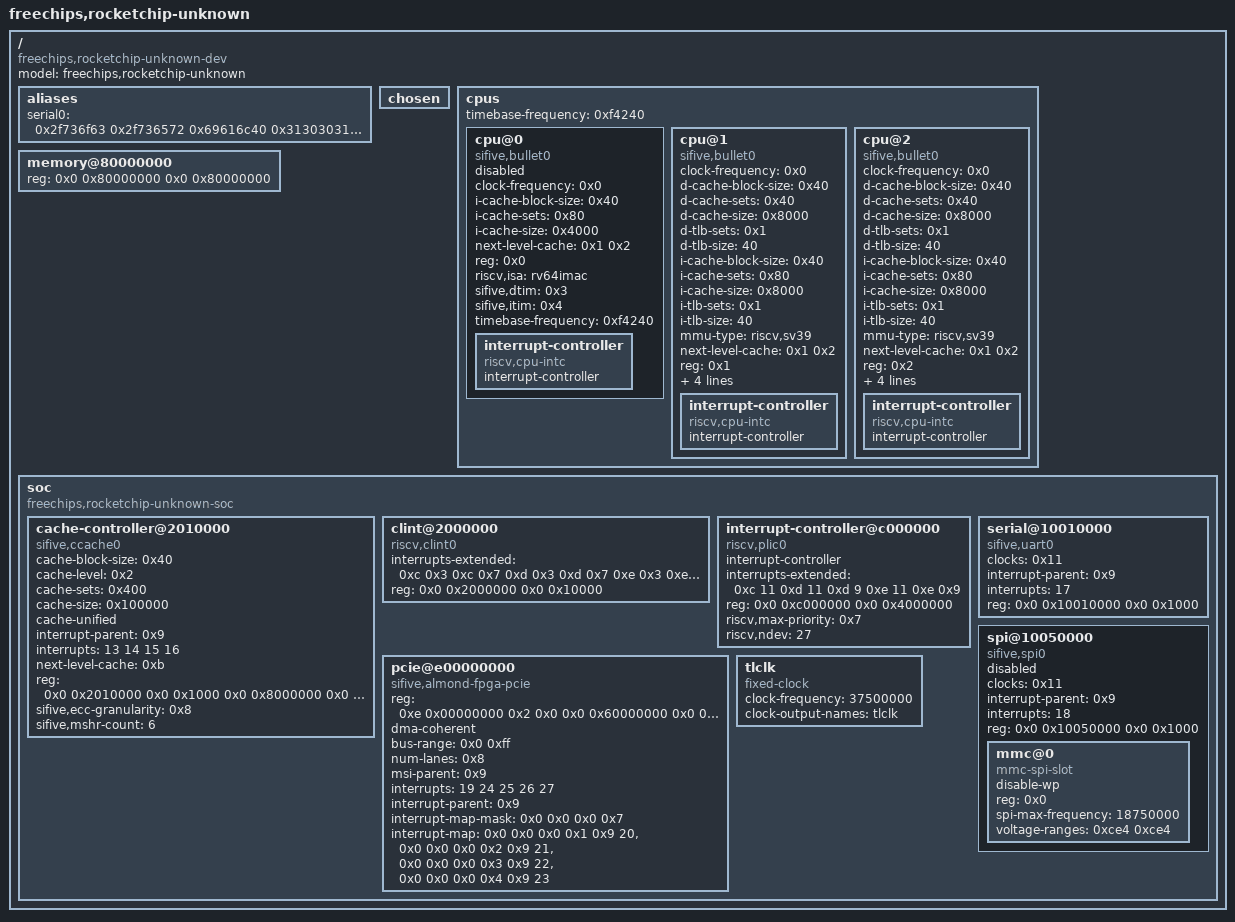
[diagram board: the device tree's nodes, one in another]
/dts-v1/;

/ {
	#address-cells = <0x2>;
	#size-cells = <0x2>;
	compatible = "freechips,rocketchip-unknown-dev";
	model = "freechips,rocketchip-unknown";

	aliases {
		serial0 = <0x2f736f63 0x2f736572 0x69616c40 0x31303031 0x30303030>;
	};

	chosen {
	};

	cpus {
		#address-cells = <0x1>;
		#size-cells = <0x0>;

                timebase-frequency = <0xf4240>;
		cpu@0 {
			clock-frequency = <0x0>;
			compatible = "sifive,bullet0", "riscv";
			device_type = "cpu";
			i-cache-block-size = <0x40>;
			i-cache-sets = <0x80>;
			i-cache-size = <0x4000>;
			next-level-cache = <0x1 0x2>;
			reg = <0x0>;
			riscv,isa = "rv64imac";
			sifive,dtim = <0x3>;
			sifive,itim = <0x4>;
			status = "masked";
			timebase-frequency = <0xf4240>;

			interrupt-controller {
				#interrupt-cells = <0x1>;
				compatible = "riscv,cpu-intc";
				interrupt-controller;
				linux,phandle = <0xc>;
				phandle = <0xc>;
			};
		};

		cpu@1 {
			clock-frequency = <0x0>;
			compatible = "sifive,bullet0", "riscv";
			d-cache-block-size = <0x40>;
			d-cache-sets = <0x40>;
			d-cache-size = <0x8000>;
			d-tlb-sets = <0x1>;
			d-tlb-size = <40>;
			device_type = "cpu";
			i-cache-block-size = <0x40>;
			i-cache-sets = <0x80>;
			i-cache-size = <0x8000>;
			i-tlb-sets = <0x1>;
			i-tlb-size = <40>;
			mmu-type = "riscv,sv39";
			next-level-cache = <0x1 0x2>;
			reg = <0x1>;
			riscv,isa = "rv64imafdc";
			sifive,itim = <0x5>;
			status = "okay";
			timebase-frequency = <0xf4240>;
			tlb-split;

			interrupt-controller {
				#interrupt-cells = <0x1>;
				compatible = "riscv,cpu-intc";
				interrupt-controller;
				linux,phandle = <0xd>;
				phandle = <0xd>;
			};
		};

		cpu@2 {
			clock-frequency = <0x0>;
			compatible = "sifive,bullet0", "riscv";
			d-cache-block-size = <0x40>;
			d-cache-sets = <0x40>;
			d-cache-size = <0x8000>;
			d-tlb-sets = <0x1>;
			d-tlb-size = <40>;
			device_type = "cpu";
			i-cache-block-size = <0x40>;
			i-cache-sets = <0x80>;
			i-cache-size = <0x8000>;
			i-tlb-sets = <0x1>;
			i-tlb-size = <40>;
			mmu-type = "riscv,sv39";
			next-level-cache = <0x1 0x2>;
			reg = <0x2>;
			riscv,isa = "rv64imafdc";
			sifive,itim = <0x6>;
			status = "okay";
			timebase-frequency = <0xf4240>;
			tlb-split;

			interrupt-controller {
				#interrupt-cells = <0x1>;
				compatible = "riscv,cpu-intc";
				interrupt-controller;
				linux,phandle = <0xe>;
				phandle = <0xe>;
			};
		};
	};

	memory@80000000 {
		device_type = "memory";
		reg = <0x0 0x80000000 0x0 0x80000000>;
		linux,phandle = <0xb>;
		phandle = <0xb>;
	};

	soc {
		#address-cells = <0x2>;
		#size-cells = <0x2>;
		compatible = "freechips,rocketchip-unknown-soc", "simple-bus";
		ranges;

		cache-controller@2010000 {
			cache-block-size = <0x40>;
			cache-level = <0x2>;
			cache-sets = <0x400>;
			cache-size = <0x100000>;
			cache-unified;
			compatible = "sifive,ccache0", "cache";
			interrupt-parent = <0x9>;
			interrupts = <13 14 15 16>;
			next-level-cache = <0xb>;
			reg = <0x0 0x2010000 0x0 0x1000 0x0 0x8000000 0x0 0x100000>;
			reg-names = "control", "sideband";
			sifive,ecc-granularity = <0x8>;
			sifive,mshr-count = <6>;
			linux,phandle = <0x2>;
			phandle = <0x2>;
		};

		clint@2000000 {
			compatible = "riscv,clint0";
			interrupts-extended = <0xc 0x3 0xc 0x7 0xd 0x3 0xd 0x7 0xe 0x3 0xe 0x7>;
			reg = <0x0 0x2000000 0x0 0x10000>;
			reg-names = "control";
		};


		interrupt-controller@c000000 {
			#interrupt-cells = <0x1>;
			compatible = "riscv,plic0";
			interrupt-controller;
			interrupts-extended = <0xc 11 0xd 11 0xd 9 0xe 11 0xe 0x9>;
			reg = <0x0 0xc000000 0x0 0x4000000>;
			reg-names = "control";
			riscv,max-priority = <0x7>;
			riscv,ndev = <27>;
			linux,phandle = <0x9>;
			phandle = <0x9>;
		};

		pcie@e00000000 {
			compatible = "sifive,almond-fpga-pcie";
			reg = <
			       0xe 0x00000000 0x2 0x0
			       0x0 0x60000000 0x0 0x80000
			       0x0 0x100d0000 0x0 0x1000>;
			reg-names = "dbi", "config", "mgmt";
			#address-cells = <0x3>;
			#size-cells = <0x2>;
			device_type = "pci";
			dma-coherent;
			bus-range = <0x0 0xff>;
			ranges = <0x81000000  0x0 0x60080000  0x0 0x60080000 0x0 0x10000	/* I/O */
			          0x82000000  0x0 0x60090000  0x0 0x60090000 0x0 0xff70000	/* mem */
			          0x82000000  0x0 0x70000000  0x0 0x70000000 0x0 0x1000000	/* mem */
				  0xc3000000 0x20 0x00000000 0x20 0x00000000 0x20 0x00000000>;  /* mem prefetchable */
			num-lanes = <0x8>;
			msi-parent = <0x9>;
			interrupts = <19 24 25 26 27>;
			interrupt-names = "msi";
			interrupt-parent = <0x9>;
			#interrupt-cells = <0x1>;
			interrupt-map-mask = <0x0 0x0 0x0 0x7>;
			interrupt-map = <0x0 0x0 0x0 0x1 0x9 20>,
					<0x0 0x0 0x0 0x2 0x9 21>,
					<0x0 0x0 0x0 0x3 0x9 22>,
					<0x0 0x0 0x0 0x4 0x9 23>;
			status = "okay";
		};

		serial@10010000 {
			clocks = <0x11>;
			compatible = "sifive,uart0";
			interrupt-parent = <0x9>;
			interrupts = <17>;
			reg = <0x0 0x10010000 0x0 0x1000>;
			reg-names = "control";
		};

		spi@10050000 {
			#address-cells = <0x1>;
			#size-cells = <0x0>;
			clocks = <0x11>;
			compatible = "sifive,spi0";
			interrupt-parent = <0x9>;
			interrupts = <18>;
			reg = <0x0 0x10050000 0x0 0x1000>;
			reg-names = "control";
			status = "disabled";

			mmc@0 {
				compatible = "mmc-spi-slot";
				disable-wp;
				reg = <0x0>;
				spi-max-frequency = <18750000>;
				voltage-ranges = <0xce4 0xce4>;
			};
		};

		tlclk {
			#clock-cells = <0x0>;
			clock-frequency = <37500000>;
			clock-output-names = "tlclk";
			compatible = "fixed-clock";
			linux,phandle = <0x11>;
			phandle = <0x11>;
		};
	};
};
